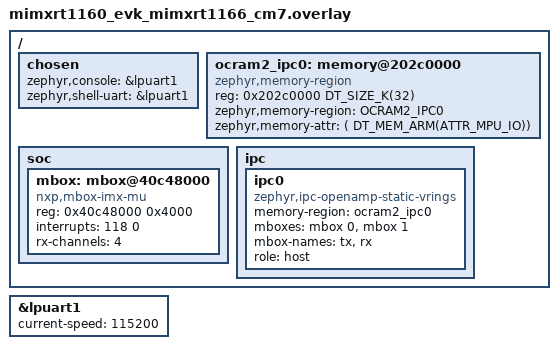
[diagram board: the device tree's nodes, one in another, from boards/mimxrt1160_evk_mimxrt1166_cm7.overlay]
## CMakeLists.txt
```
# Copyright (c) 2018 Nordic Semiconductor ASA
# Copyright (c) 2019 Linaro Limited
# Copyright 2022 NXP
#
# SPDX-License-Identifier: Apache-2.0
#

cmake_minimum_required(VERSION 3.20.0)

set(CM4_BIN_ZEPHYR_DIR ${CMAKE_CURRENT_BINARY_DIR}/../cm4/zephyr)

find_package(Zephyr REQUIRED HINTS $ENV{ZEPHYR_BASE})

project(openamp_rust_cm7)

# Add Rust support
find_program(CARGO cargo REQUIRED)
message(STATUS "${BOARD} compiles as the Master in this sample")

# Add source files
target_sources(app PRIVATE src/main.c)

# Add include directories
target_include_directories(app PRIVATE ${CMAKE_CURRENT_SOURCE_DIR}/src)
target_include_directories(app PRIVATE ${CMAKE_CURRENT_SOURCE_DIR}/../common/include)
if(CONFIG_INCLUDE_REMOTE_DIR)
  target_include_directories(zephyr_interface
    INTERFACE ${CM4_BIN_ZEPHYR_DIR}/include/public)
endif()

# Add rust library
add_dependencies(app rust_lib)

# Rust library configuration
set(RUST_LIB_DIR ${CMAKE_CURRENT_SOURCE_DIR}/rust_lib)
set(RUST_TARGET_DIR ${CMAKE_CURRENT_BINARY_DIR}/rust_target)
set(RUST_TARGET thumbv7m-none-eabi)
#set(RUST_TARGET thumbv7em-none-eabihf)

# Build Rust library
add_custom_command(
    OUTPUT ${RUST_TARGET_DIR}/${RUST_TARGET}/release/librust_openamp.a
    COMMAND ${CMAKE_COMMAND} -E env
        CARGO_TARGET_DIR=${RUST_TARGET_DIR}
        "RUSTFLAGS=-C target-cpu=cortex-m7"
        ${CARGO} build --release --target ${RUST_TARGET}
    WORKING_DIRECTORY ${RUST_LIB_DIR}
    DEPENDS ${RUST_LIB_DIR}/src/lib.rs ${RUST_LIB_DIR}/Cargo.toml
    COMMENT "Building Rust library for CM7"
)

add_custom_target(rust_lib ALL
    DEPENDS ${RUST_TARGET_DIR}/${RUST_TARGET}/release/librust_openamp.a
)

# Link Rust library
target_link_libraries(app PRIVATE ${RUST_TARGET_DIR}/${RUST_TARGET}/release/librust_openamp.a)
```

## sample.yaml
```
sample:
  description: This app provides an example of how to integrate OpenAMP with Zephyr.
  name: OpenAMP example integration
tests:
  sample.ipc.openamp:
    platform_allow:
      - mimxrt1160_evk/mimxrt1166/cm7
      - mimxrt1160_evk/mimxrt1166/cm4
    integration_platforms:
      - mimxrt1160_evk/mimxrt1166/cm7
    tags:
      - ipm
      - openamp
    harness: console
    sysbuild: true
    harness_config:
      type: multi_line
      regex:
        - "Master core received a message: 1"
        - "Master core received a message: 99"
        - "OpenAMP demo ended."
```

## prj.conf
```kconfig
# Enable OpenAMP
CONFIG_OPENAMP=y
CONFIG_OPENAMP_RSC_TABLE=y

# Enable IPC
CONFIG_IPC_SERVICE=y
CONFIG_IPC_SERVICE_BACKEND_RPMSG=y
CONFIG_IPC_SERVICE_STATIC_VRINGS=y

# Enable console and logging
CONFIG_CONSOLE=y
CONFIG_UART_CONSOLE=y
CONFIG_LOG=y
CONFIG_LOG_DEFAULT_LEVEL=3

# Memory configuration
CONFIG_MAIN_STACK_SIZE=4096
CONFIG_HEAP_MEM_POOL_SIZE=16384

# Enable mailbox for inter-core communication
CONFIG_MBOX=y
CONFIG_MBOX_NXP_IMX_MU=y

# Rust support
CONFIG_CPP=y
CONFIG_NEWLIB_LIBC=y
CONFIG_NEWLIB_LIBC_FLOAT_PRINTF=y

# Enable second core support for single-core builds
CONFIG_SECOND_CORE_MCUX=y
```

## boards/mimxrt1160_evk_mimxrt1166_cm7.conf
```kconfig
CONFIG_INCLUDE_REMOTE_DIR=y
CONFIG_MBOX_NXP_IMX_MU=y
CONFIG_SECOND_CORE_MCUX=y
```

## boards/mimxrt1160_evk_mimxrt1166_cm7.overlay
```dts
/*
 * Copyright (c) 2022 NXP
 *
 * SPDX-License-Identifier: Apache-2.0
 */

#include <zephyr/dt-bindings/ipc_service/static_vrings.h>
#include <zephyr/dt-bindings/memory-attr/memory-attr-arm.h>

/ {
	chosen {
		/* Delete ipc chosen property where old IPM mailbox driver below is
		 * configured.
		 */
		/delete-property/ zephyr,ipc;
		/delete-property/ zephyr,ipc_shm;

		zephyr,console = &lpuart1;
		zephyr,shell-uart = &lpuart1;
	};

	/* Define memory regions for IPC
	 * Note that shared memory must have specific MPU attributes set.
	 */
	 ocram2_ipc0: memory@202c0000{
		compatible = "zephyr,memory-region", "mmio-sram";
		reg = <0x202c0000 DT_SIZE_K(32)>;
		zephyr,memory-region="OCRAM2_IPC0";
		zephyr,memory-attr = <( DT_MEM_ARM(ATTR_MPU_IO))>;
	};

	soc {
		/* Delete IPM Driver node nxp,imx-mu */
		/delete-node/ mailbox@40c48000;

		/* Attach MBOX driver to MU Unit */
		mbox:mbox@40c48000 {
			compatible = "nxp,mbox-imx-mu";
			reg = <0x40c48000 0x4000>;
			interrupts = <118 0>;
			rx-channels = <4>;
			#mbox-cells = <1>;
			status = "okay";
		};
	};

	ipc {
		/delete-node/ ipc0;

		ipc0: ipc0 {
			compatible = "zephyr,ipc-openamp-static-vrings";
			memory-region = <&ocram2_ipc0>;
			mboxes = <&mbox 0>, <&mbox 1>;
			mbox-names = "tx", "rx";
			role = "host";
			status = "okay";
		};
	};
};

&lpuart1 {
	status = "okay";
	current-speed = <115200>;
};
```

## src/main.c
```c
/*
 * Copyright (c) 2024, Blue-leap
 *
 * SPDX-License-Identifier: Apache-2.0
 */

#include <openamp_common.h>

LOG_MODULE_REGISTER(cm7_main, LOG_LEVEL_DBG);

/* Local endpoint */
static struct ipc_ept ep;

/* Semaphore to wait for endpoint binding */
static K_SEM_DEFINE(bound_sem, 0, 1);

/*
 * @brief Endpoint bound callback
 *
 * This function is called when the remote core binds to the endpoint.
 *
 * @param priv Private data
 */
static void ep_bound(void *priv)
{
	LOG_INF("IPC endpoint bound");
	k_sem_give(&bound_sem);
}

/*
 * @brief Message reception callback
 *
 * This function is called when a message is received from the remote core.
 *
 * @param data Received data
 * @param len Length of the received data
 * @param priv Private data
 */
static void ep_recv(const void *data, size_t len, void *priv)
{
	rust_openamp_process_received(data, len);
}

static const struct ipc_ept_cfg ep_cfg = {
	.name = "ep0",
	.cb = {
		.bound = ep_bound,
		.received = ep_recv,
	},
};

int main(void)
{
	const struct device *const ipc0_instance = DEVICE_DT_GET(DT_NODELABEL(ipc0));
	int ret;

	LOG_INF("Starting CM7 application");

	/* Initialize Rust OpenAMP library */
	rust_openamp_init();

	ret = ipc_service_open_instance(ipc0_instance);
	if (ret < 0 && ret != -EALREADY) {
		LOG_ERR("Failed to open IPC instance: %d", ret);
		return ret;
	}

	/* Wait a bit to give the CM4 core time to register its endpoint first */
	k_sleep(K_MSEC(1000));

	ret = ipc_service_register_endpoint(ipc0_instance, &ep, &ep_cfg);
	if (ret < 0) {
		LOG_ERR("Failed to register endpoint: %d", ret);
		return ret;
	}

	/* Wait for the endpoint to be bound */
	k_sem_take(&bound_sem, K_FOREVER);

	while (1) {
		char message[64];
		static uint32_t count = 0;

		/* Format the message to be sent */
		snprintf(message, sizeof(message), "Hello from CM7, count: %u", count++);

		/* Send the message to the remote core */
		rust_openamp_send_message(message);
		ret = ipc_service_send(&ep, message, strlen(message));
		if (ret < 0) {
			LOG_ERR("Failed to send message: %d", ret);
		}

		k_msleep(1000);
	}

	return 0;
}
```

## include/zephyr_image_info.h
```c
/* Dummy header to satisfy single-core build */
```
